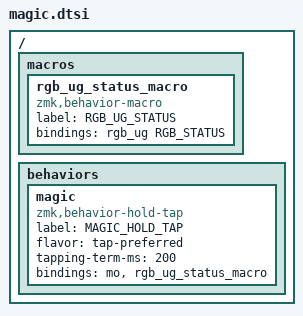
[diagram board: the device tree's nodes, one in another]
#include <dt-bindings/zmk/rgb.h>

/ {
    macros {
        rgb_ug_status_macro: rgb_ug_status_macro {
            label = "RGB_UG_STATUS";
            compatible = "zmk,behavior-macro";
            #binding-cells = <0>;
            bindings
                = <&rgb_ug RGB_STATUS>;
        };
    };
};

/ {
    behaviors {
        magic: magic {
            compatible = "zmk,behavior-hold-tap";
            label = "MAGIC_HOLD_TAP";
            #binding-cells = <2>;
            flavor = "tap-preferred";
            tapping-term-ms = <200>;
            bindings = <&mo>, <&rgb_ug_status_macro>;
        };
    };
};
